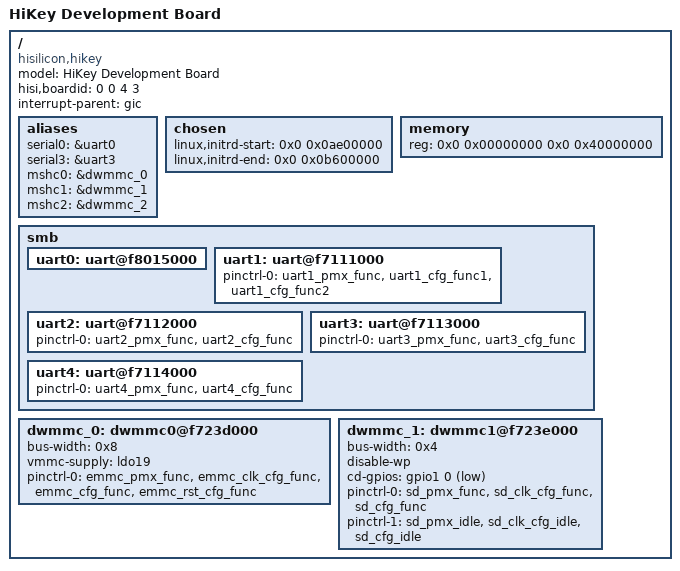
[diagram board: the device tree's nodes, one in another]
/*
 * dts file for Hisilicon HiKey Development Board
 *
 * Copyright (C) 2014, Hisilicon Ltd.
 *
 */

/dts-v1/;

/memreserve/ 0x00000000 0x07400000;
/memreserve/ 0x0740f000 0x1000;

#include "hikey-pinctrl.dtsi"
#include "hikey-gpio.dtsi"
#include "hi6220.dtsi"

/ {
	model = "HiKey Development Board";
	compatible = "hisilicon,hikey";
	hisi,boardid = <0 0 4 3>;
	#address-cells = <2>;
	#size-cells = <2>;
	interrupt-parent = <&gic>;

	aliases {
		serial0 = &uart0;
		serial3 = &uart3;
		mshc0 = &dwmmc_0;
		mshc1 = &dwmmc_1;
		mshc2 = &dwmmc_2;
	};

	chosen {
		linux,initrd-start = <0x0 0x0ae00000>;
		linux,initrd-end = <0x0 0x0b600000>;
	};

	memory {
		device_type = "memory";
		reg = <0x0 0x00000000 0x0 0x40000000>;
	};

	smb {
		uart0: uart@f8015000 {	/* console */
			status = "ok";
		};

		uart1: uart@f7111000 {
			pinctrl-names = "default";
			pinctrl-0 = <&uart1_pmx_func
				     &uart1_cfg_func1 &uart1_cfg_func2>;
			status = "ok";
		};

		uart2: uart@f7112000 {
			pinctrl-names = "default";
			pinctrl-0 = <&uart2_pmx_func &uart2_cfg_func>;
			status = "ok";
		};

		uart3: uart@f7113000 {
			pinctrl-names = "default";
			pinctrl-0 = <&uart3_pmx_func &uart3_cfg_func>;
			status = "ok";
		};

		uart4: uart@f7114000 {
			pinctrl-names = "default";
			pinctrl-0 = <&uart4_pmx_func &uart4_cfg_func>;
			status = "ok";
		};
   };

	dwmmc_0: dwmmc0@f723d000 {
		bus-width = <0x8>;
		vmmc-supply = <&ldo19>;
		pinctrl-names = "default";
		pinctrl-0 = <&emmc_pmx_func &emmc_clk_cfg_func
			     &emmc_cfg_func &emmc_rst_cfg_func>;
	};

	dwmmc_1: dwmmc1@f723e000 {
		bus-width = <0x4>;
		disable-wp;
		cd-gpios = <&gpio1 0 1>;
		pinctrl-names = "default", "idle";
		pinctrl-0 = <&sd_pmx_func &sd_clk_cfg_func &sd_cfg_func>;
		pinctrl-1 = <&sd_pmx_idle &sd_clk_cfg_idle &sd_cfg_idle>;
	};
};
